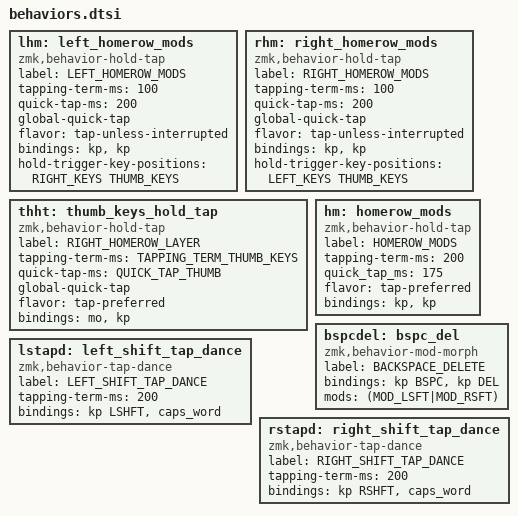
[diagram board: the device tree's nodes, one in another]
#define str(s) #s

#define LEFT_KEYS 0  1  2  3  4  5  6 14 15 16 17 18 19 20 28 29 30 31 32 33 34 42 43 44 45 46 47 54 55 56 57 58  
#define RIGHT_KEYS 7  8  9  10 11 12 13 21 22 23 24 25 26 27 35 36 37 38 39 40 41 48 49 50 51 52 53 59 60 61 62 63
#define THUMBS_LEFT 64 65 68 70 71 72
#define THUMBS_RIGHT 66 67 69 73 74 75
#define THUMB_KEYS THUMBS_LEFT THUMBS_RIGHT

#define TAPPING_TERM_HOMEROW 200
#define TAPPING_TERM_THUMB_KEYS 200
#define QUICK_TAP_HOMEROW 100
#define QUICK_TAP_THUMB 180

#define MOD_MORPH(NAME, KEY, MOD_KEY, MODS) (mm_##NAME: mm_##NAME { \
    compatible = "zmk,behavior-mod-morph"; \
    label = str(NAME); \
    #binding-cells = <0>; \
    bindings = <&kp KEY>, <&kp MOD_KEY>; \
    mods = <MODS>; \
  };)

/* Programmer's Dvorak shifts morphs // EW: some prior example*/
    /*
    MOD_MORPH(dllr_hash,  DLLR,  HASH,  (MOD_LSFT|MOD_RSFT))
    MOD_MORPH(n1_plus,    PLUS,  N1,    (MOD_LSFT|MOD_RSFT))
    MOD_MORPH(n2_lbkt,    LBKT,  N2,    (MOD_LSFT|MOD_RSFT))
    MOD_MORPH(n3_lbrc,    LBRC,  N3,    (MOD_LSFT|MOD_RSFT))
    MOD_MORPH(n4_lpar,    LPAR,  N4,    (MOD_LSFT|MOD_RSFT))
    MOD_MORPH(n5_amps,    AMPS,  N5,    (MOD_LSFT|MOD_RSFT))
    MOD_MORPH(n6_equal,   EQUAL, N6,    (MOD_LSFT|MOD_RSFT))
    MOD_MORPH(n7_rpar,    RPAR,  N7,    (MOD_LSFT|MOD_RSFT))
    MOD_MORPH(n8_rbrc,    RBRC,  N8,    (MOD_LSFT|MOD_RSFT))
    MOD_MORPH(n9_rbkt,    RBKT,  N9,    (MOD_LSFT|MOD_RSFT))
    MOD_MORPH(n0_star,    STAR,  N0,    (MOD_LSFT|MOD_RSFT))
    MOD_MORPH(excl_prcnt, EXCL,  PRCNT, (MOD_LSFT|MOD_RSFT))
    MOD_MORPH(at_caret,   AT,    CARET, (MOD_LSFT|MOD_RSFT))
    */

/* Eric Colemak #s with alt Punctuation*/
    MOD_MORPH(cmk_grave_n1,  GRAVE,     N1, (MOD_LSFT|MOD_RSFT))
    MOD_MORPH(cmk_at_n2,     AT,        N2, (MOD_LSFT|MOD_RSFT))
    MOD_MORPH(cmk_star_n3,   STAR,      N3, (MOD_LSFT|MOD_RSFT))
    MOD_MORPH(cmk_amps_n4,   AMPS,      N4, (MOD_LSFT|MOD_RSFT))
    MOD_MORPH(cmk_tilde_n5,  TILDE,     N5, (MOD_LSFT|MOD_RSFT))
    MOD_MORPH(cmk_caret_n6,  CARET,     N6, (MOD_LSFT|MOD_RSFT))
    MOD_MORPH(cmk_dllr_n7,   DLLR,      N7, (MOD_LSFT|MOD_RSFT))
    MOD_MORPH(cmk_hash_n8,   HASH,      N8, (MOD_LSFT|MOD_RSFT))
    MOD_MORPH(cmk_prcnt_n9,  PRCNT,     N9, (MOD_LSFT|MOD_RSFT))
    MOD_MORPH(cmk_lsF24_n0,  LS(F24),   N0, (MOD_LSFT|MOD_RSFT))

/* ^ NOTES
        * need the "MOD_" version of the key
        * must be inside <> and within () inside that
        * PIPE delimited list

*/



lhm: left_homerow_mods {
    compatible = "zmk,behavior-hold-tap";
    label = "LEFT_HOMEROW_MODS";
    #binding-cells = <2>;
    tapping-term-ms = <100>;
    quick-tap-ms = <200>;
    global-quick-tap;
    flavor = "tap-unless-interrupted";
    bindings = <&kp>, <&kp>;
    hold-trigger-key-positions = <RIGHT_KEYS THUMB_KEYS>;
};

rhm: right_homerow_mods {
    compatible = "zmk,behavior-hold-tap";
    label = "RIGHT_HOMEROW_MODS";
    #binding-cells = <2>;
    tapping-term-ms = <100>;
    quick-tap-ms = <200>;
    global-quick-tap;
    flavor = "tap-unless-interrupted";
    bindings = <&kp>, <&kp>;
    hold-trigger-key-positions = <LEFT_KEYS THUMB_KEYS>;
};

thht: thumb_keys_hold_tap {
    compatible = "zmk,behavior-hold-tap";
    label = "RIGHT_HOMEROW_LAYER";
    #binding-cells = <2>;
    tapping-term-ms = <TAPPING_TERM_THUMB_KEYS>;
    quick-tap-ms = <QUICK_TAP_THUMB>;
    global-quick-tap;
    flavor = "tap-preferred";
    bindings = <&mo>, <&kp>;
};

hm: homerow_mods {
    compatible = "zmk,behavior-hold-tap";
    label = "HOMEROW_MODS";
    #binding-cells = <2>;
    tapping-term-ms = <200>;
    quick_tap_ms = <175>;
    flavor = "tap-preferred";
    bindings = <&kp>, <&kp>;
};

bspcdel: bspc_del {
    compatible = "zmk,behavior-mod-morph";
    label = "BACKSPACE_DELETE";
    #binding-cells = <0>;
    bindings = <&kp BSPC>, <&kp DEL>;
    mods = <(MOD_LSFT|MOD_RSFT)>;
};

lstapd: left_shift_tap_dance {
    compatible = "zmk,behavior-tap-dance";
    label = "LEFT_SHIFT_TAP_DANCE";
    #binding-cells = <0>;
    tapping-term-ms = <200>;
    bindings = <&kp LSHFT>, <&caps_word>;
};

rstapd: right_shift_tap_dance {
    compatible = "zmk,behavior-tap-dance";
    label = "RIGHT_SHIFT_TAP_DANCE";
    #binding-cells = <0>;
    tapping-term-ms = <200>;
    bindings = <&kp RSHFT>, <&caps_word>;
};
